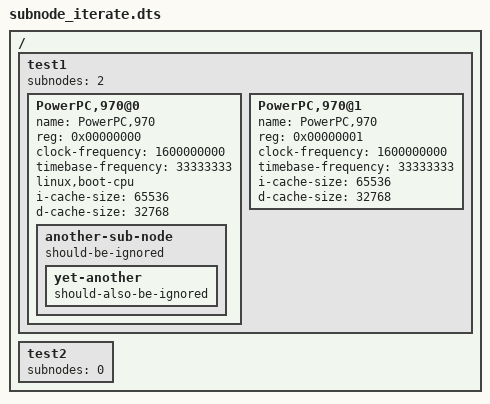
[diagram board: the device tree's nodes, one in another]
/dts-v1/;

/ {
	#address-cells = <1>;
	#size-cells = <0>;

	test1 {
		subnodes = <2>;
		linux,phandle = <0x1>;
		#address-cells = <1>;
		#size-cells = <0>;
		PowerPC,970@0 {
			name = "PowerPC,970";
			device_type = "cpu";
			reg = <0x00000000>;
			clock-frequency = <1600000000>;
			timebase-frequency = <33333333>;
			linux,boot-cpu;
			i-cache-size = <65536>;
			d-cache-size = <32768>;
			another-sub-node {
				should-be-ignored;
				yet-another {
					should-also-be-ignored;
				};
			};
		};

		PowerPC,970@1 {
			name = "PowerPC,970";
			device_type = "cpu";
			reg = <0x00000001>;
			clock-frequency = <1600000000>;
			timebase-frequency = <33333333>;
			i-cache-size = <65536>;
			d-cache-size = <32768>;
		};
	};

	test2 {
		subnodes = <0>;
	};
};

